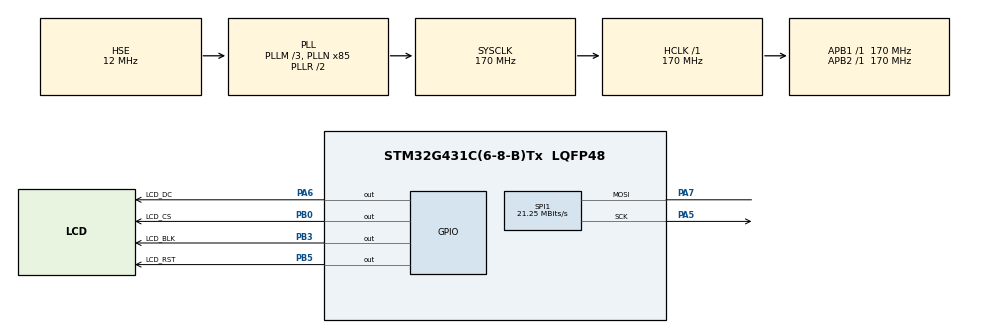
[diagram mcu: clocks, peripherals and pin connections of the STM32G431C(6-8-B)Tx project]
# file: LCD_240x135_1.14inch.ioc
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Mcu.Family=STM32G4
Mcu.Name=STM32G431C(6-8-B)Tx
Mcu.Package=LQFP48
NVIC.PriorityGroup=NVIC_PRIORITYGROUP_4
PA5.GPIO_PuPd=GPIO_PULLUP
PA5.GPIO_Speed=GPIO_SPEED_FREQ_VERY_HIGH
PA5.Mode=Simplex_Bidirectional_Master
PA5.Signal=SPI1_SCK
PA6.GPIO_Label=LCD_DC
PA6.Signal=GPIO_Output
PA7.GPIO_PuPd=GPIO_PULLUP
PA7.GPIO_Speed=GPIO_SPEED_FREQ_VERY_HIGH
PA7.Mode=Simplex_Bidirectional_Master
PA7.Signal=SPI1_MOSI
PB0.GPIO_Label=LCD_CS
PB0.Signal=GPIO_Output
PB3.GPIO_Label=LCD_BLK
PB3.Signal=GPIO_Output
PB5.GPIO_Label=LCD_RST
PB5.Signal=GPIO_Output
PF0-OSC_IN.Mode=HSE-External-Oscillator
PF0-OSC_IN.Signal=RCC_OSC_IN
PF1-OSC_OUT.Mode=HSE-External-Oscillator
PF1-OSC_OUT.Signal=RCC_OSC_OUT
ProjectManager.HeapSize=0x200
ProjectManager.StackSize=0x400
ProjectManager.TargetToolchain=MDK-ARM V5.32
RCC.ADC12Freq_Value=170000000
RCC.AHBFreq_Value=170000000
RCC.APB1Freq_Value=170000000
RCC.APB1TimFreq_Value=170000000
RCC.APB2Freq_Value=170000000
RCC.APB2TimFreq_Value=170000000
RCC.CortexFreq_Value=170000000
RCC.EXTERNAL_CLOCK_VALUE=12288000
RCC.FLatency=FLASH_LATENCY_4
RCC.HCLKFreq_Value=170000000
RCC.HSE_VALUE=12000000
RCC.HSI48_VALUE=48000000
RCC.HSI_VALUE=16000000
RCC.LSE_VALUE=32768
RCC.PLLM=RCC_PLLM_DIV3
RCC.PLLN=85
RCC.PLLSourceVirtual=RCC_PLLSOURCE_HSE
RCC.SYSCLKFreq_VALUE=170000000
RCC.SYSCLKSource=RCC_SYSCLKSOURCE_PLLCLK
RCC.USBFreq_Value=170000000
RCC.VCOOutputFreq_Value=340000000
SPI1.BaudRatePrescaler=SPI_BAUDRATEPRESCALER_8
SPI1.CLKPhase=SPI_PHASE_2EDGE
SPI1.CLKPolarity=SPI_POLARITY_HIGH
SPI1.CRCCalculation=SPI_CRCCALCULATION_DISABLE
SPI1.CalculateBaudRate=21.25 MBits/s
SPI1.DataSize=SPI_DATASIZE_8BIT
SPI1.Direction=SPI_DIRECTION_1LINE
SPI1.FirstBit=SPI_FIRSTBIT_MSB
SPI1.Mode=SPI_MODE_MASTER
SPI1.NSS=SPI_NSS_SOFT
SPI1.TIMode=SPI_TIMODE_DISABLE
SPI1.VirtualType=VM_MASTER
VP_SYS_VS_DBSignals.Mode=DisableDeadBatterySignals
board=custom

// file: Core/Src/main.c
/* USER CODE BEGIN Header */
/**
  ******************************************************************************
  * @file           : main.c
  * @brief          : Main program body
  ******************************************************************************
  * @attention
  *
  * Copyright (c) 2022 STMicroelectronics.
  * All rights reserved.
  *
  * This software is licensed under terms that can be found in the LICENSE file
  * in the root directory of this software component.
  * If no LICENSE file comes with this software, it is provided AS-IS.
  *
  ******************************************************************************
  */
/* USER CODE END Header */
#include "main.h"
#include "spi.h"
#include "gpio.h"

/* USER CODE BEGIN Includes */
#include "lcd.h"
#include "picture.h"
#include "picture1.h"
#include "picture2.h"
#include "logo.h"

/* USER CODE END Includes */

void SystemClock_Config(void);

int main(void)
{

  /* MCU Configuration--------------------------------------------------------*/

  /* Reset of all peripherals, Initializes the Flash interface and the Systick. */
  HAL_Init();

  /* Configure the system clock */
  SystemClock_Config();

  /* Initialize all configured peripherals */
  MX_GPIO_Init();
  MX_SPI1_Init();
  /* USER CODE BEGIN 2 */
	Lcd_Init();
	Lcd_Clear(BLACK);

		Lcd_ShowPicture(0, 0, 240, 135, gImage_picture1);
//	Lcd_ShowPicture(0, 20, 80, 80, logo);
//	Lcd_print( 120,   0,   RED, "X Pulse");
//	Lcd_print( 120,  30,  BLUE, "X Pulse");
//	Lcd_print( 120,  60, GREEN, "X Pulse");
//	Lcd_print(45, 115, LIGHTBLUE, "2023-01-01 00:00:01");
  /* USER CODE END 2 */

  /* Infinite loop */
  while (1)
  {

  }
}

void SystemClock_Config(void)
{
  RCC_OscInitTypeDef RCC_OscInitStruct = {0};
  RCC_ClkInitTypeDef RCC_ClkInitStruct = {0};

  /** Configure the main internal regulator output voltage
  */
  HAL_PWREx_ControlVoltageScaling(PWR_REGULATOR_VOLTAGE_SCALE1_BOOST);

  /** Initializes the RCC Oscillators according to the specified parameters
  * in the RCC_OscInitTypeDef structure.
  */
  RCC_OscInitStruct.OscillatorType = RCC_OSCILLATORTYPE_HSE;
  RCC_OscInitStruct.HSEState = RCC_HSE_ON;
  RCC_OscInitStruct.PLL.PLLState = RCC_PLL_ON;
  RCC_OscInitStruct.PLL.PLLSource = RCC_PLLSOURCE_HSE;
  RCC_OscInitStruct.PLL.PLLM = RCC_PLLM_DIV3;
  RCC_OscInitStruct.PLL.PLLN = 85;
  RCC_OscInitStruct.PLL.PLLP = RCC_PLLP_DIV2;
  RCC_OscInitStruct.PLL.PLLQ = RCC_PLLQ_DIV2;
  RCC_OscInitStruct.PLL.PLLR = RCC_PLLR_DIV2;
  if (HAL_RCC_OscConfig(&RCC_OscInitStruct) != HAL_OK)
  {
    Error_Handler();
  }

  /** Initializes the CPU, AHB and APB buses clocks
  */
  RCC_ClkInitStruct.ClockType = RCC_CLOCKTYPE_HCLK|RCC_CLOCKTYPE_SYSCLK
                              |RCC_CLOCKTYPE_PCLK1|RCC_CLOCKTYPE_PCLK2;
  RCC_ClkInitStruct.SYSCLKSource = RCC_SYSCLKSOURCE_PLLCLK;
  RCC_ClkInitStruct.AHBCLKDivider = RCC_SYSCLK_DIV1;
  RCC_ClkInitStruct.APB1CLKDivider = RCC_HCLK_DIV1;
  RCC_ClkInitStruct.APB2CLKDivider = RCC_HCLK_DIV1;

  if (HAL_RCC_ClockConfig(&RCC_ClkInitStruct, FLASH_LATENCY_4) != HAL_OK)
  {
    Error_Handler();
  }
}

void Error_Handler(void)
{
  __disable_irq();
  while (1)
  {
  }
}
